# PIC32CX0525SG12144 register map
Vendor: Microchip Technology; Series: 0525SG12; File version: 0
CPU: CM4 r1p0, little endian, no MPU, no FPU, 3 interrupt priority bits, 172 interrupts
Registers are 32-bit, read-write, reset 0x0 unless marked. A register's access mark holds for its fields unless they carry their own. Offsets are from the block's base; [hi:lo] are bit positions; {n}, {i} and the like mark numbered series; 'fields as' and 'values as' point back to an identical list.

## ESPI_SMVW00_10 — The ESPI VW Channel permits the System to emulate a set of wires that interconnect the system Core Logic with the EC
Base 0x400F9E00; register names take the prefix ESPI_SMVW00_1_
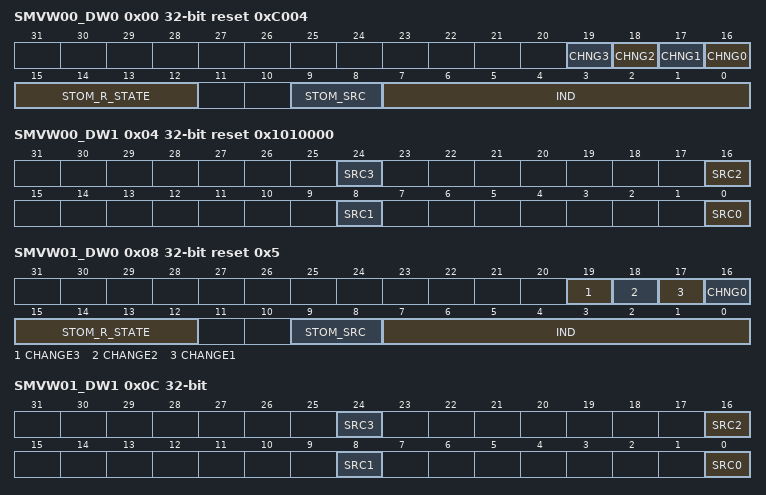
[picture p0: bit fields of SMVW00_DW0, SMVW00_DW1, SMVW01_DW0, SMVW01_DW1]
0x00 SMVW00_DW0 reset 0xC004 — Slave-to-Master Virtual Wire 0 Register (DWord 0)
  [n+16] CHNG{n} (n=0..3) — This bit is set to 1 whenever the value in Bit{n} in this register changes. This bit is set to 0 whenever the 4 data bits in this register are transmitted to the Host by a Slave-to-Master Virtual Wire transaction. It is also set to 0 when this entire register is reset, ignoring any change in the data bit value caused by the reset event.
  [15:12] STOM_R_STATE — The four bits in this field are loaded into SRC0, SRC1, SRC2 and SRC3 when the reset signal selected by S2M RESET SRC is asserted. If STOM_SRC is set for RESET_SYS, the SRC bits are set to the default value of this field, rather than its programmed value, since this field is also reset on RESET_SYS.
  [9:8] STOM_SRC — This field determines which reset signal in addition to RESET_SYS resets SRC[3:0] in this register: 3=PLTRST. 2=RESET_SIO. 1=RESET_SYS. This is the only reset signal that will reset the SRC fields. 0=RESET_ESPI.
  [7:0] IND — The Index for SRC0, SRC1, SRC2 and SRC3. A write to this register that changes the value of any one or more of SRC0, SRC1, SRC2 or SRC3 will generate a Slave-to-Master Virtual Wire transaction with this index. Setting the INDEX field to 0 disables the register from generating any Virtual Wire traffic to the Master. Setting the INDEX field to 1 is illegal, since INDEX=1 is reserved for Serial IRQ.
0x04 SMVW00_DW1 reset 0x1010000 — Slave-to-Master Virtual Wire 0 Register (DWord 1)
  [8n] SRC{n} (n=0..3) — Slave-to-Master data for Bit Position {n} for the virtual wire associated with the index defined by INDEX. The most recent value of this bit is transmitted to the Master, even if the bit changes multiple times before the Master issues the Virtual Wire read transaction.
0x08 SMVW01_DW0 reset 0x5 — Slave-to-Master Virtual Wire 1 Register (DWord 0)
  [19] CHANGE3 — This bit is set to 1 whenever the value in Bit3 in this register changes. This bit is set to 0 whenever the 4 data bits in this register are transmitted to the Host by a Slave-to-Master Virtual Wire transaction. It is also set to 0 when this entire register is reset, ignoring any change in the data bit value caused by the reset event.
  [18] CHANGE2 — This bit is set to 1 whenever the value in Bit2 in this register changes. This bit is set to 0 whenever the 4 data bits in this register are transmitted to the Host by a Slave-to-Master Virtual Wire transaction. It is also set to 0 when this entire register is reset, ignoring any change in the data bit value caused by the reset event.
  [17] CHANGE1 — This bit is set to 1 whenever the value in Bit1 in this register changes. This bit is set to 0 whenever the 4 data bits in this register are transmitted to the Host by a Slave-to-Master Virtual Wire transaction. It is also set to 0 when this entire register is reset, ignoring any change in the data bit value caused by the reset event.
  [16] CHNG0 — This bit is set to 1 whenever the value in Bit0 in this register changes. This bit is set to 0 whenever the 4 data bits in this register are transmitted to the Host by a Slave-to-Master Virtual Wire transaction. It is also set to 0 when this entire register is reset, ignoring any change in the data bit value caused by the reset event.
  [15:12] STOM_R_STATE — The four bits in this field are loaded into SRC0, SRC1, SRC2 and SRC3 when the reset signal selected by S2M RESET SRC is asserted. If STOM_SRC is set for RESET_SYS, the SRC bits are set to the default value of this field, rather than its programmed value, since this field is also reset on RESET_SYS.
  [9:8] STOM_SRC — This field determines which reset signal in addition to RESET_SYS resets SRC[3:0] in this register: 3=PLTRST. 2=RESET_SIO. 1=RESET_SYS. This is the only reset signal that will reset the SRC fields. 0=RESET_ESPI.
  [7:0] IND — The Index for SRC0, SRC1, SRC2 and SRC3. A write to this register that changes the value of any one or more of SRC0, SRC1, SRC2 or SRC3 will generate a Slave-to-Master Virtual Wire transaction with this index. Setting the INDEX field to 0 disables the register from generating any Virtual Wire traffic to the Master. Setting the INDEX field to 1 is illegal, since INDEX=1 is reserved for Serial IRQ.
0x0C SMVW01_DW1 — Slave-to-Master Virtual Wire 1 Register (DWord 1)
  fields as SMVW00_DW1
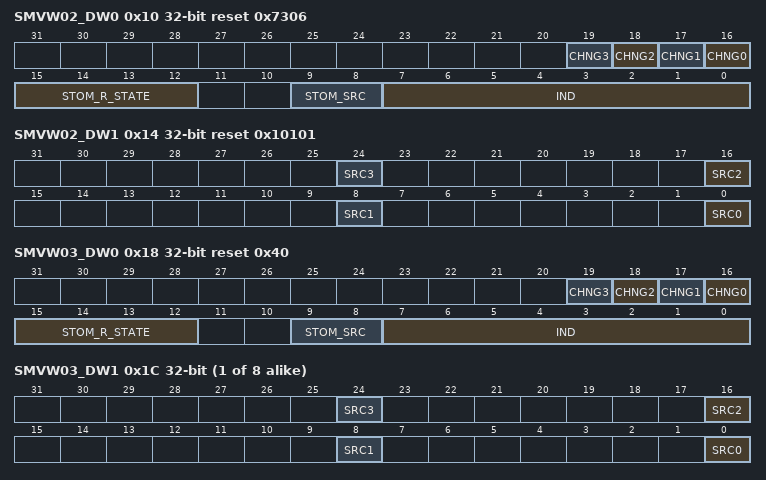
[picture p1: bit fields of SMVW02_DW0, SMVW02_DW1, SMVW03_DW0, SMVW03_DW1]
0x10 SMVW02_DW0 reset 0x7306 — Slave-to-Master Virtual Wire 2 Register (DWord 0)
  fields as SMVW00_DW0
0x14 SMVW02_DW1 reset 0x10101 — Slave-to-Master Virtual Wire 2 Register (DWord 1)
  fields as SMVW00_DW1
0x18 SMVW03_DW0 reset 0x40 — Slave-to-Master Virtual Wire 3 Register (DWord 0)
  fields as SMVW00_DW0
{0x4+8i} SMVW{i:02}_DW1 (i=3..10) — Slave-to-Master Virtual Wire {i} Register (DWord 1)
  fields as SMVW00_DW1
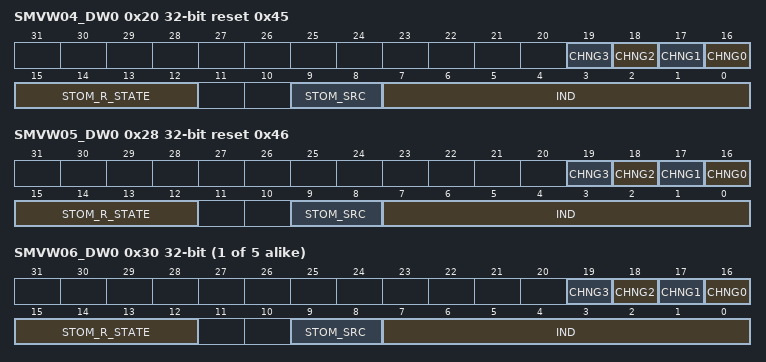
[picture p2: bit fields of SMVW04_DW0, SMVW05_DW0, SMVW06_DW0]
0x20 SMVW04_DW0 reset 0x45 — Slave-to-Master Virtual Wire 4 Register (DWord 0)
  fields as SMVW00_DW0
0x28 SMVW05_DW0 reset 0x46 — Slave-to-Master Virtual Wire 5 Register (DWord 0)
  fields as SMVW00_DW0
{0x0+8i} SMVW{i:02}_DW0 (i=6..10) — Slave-to-Master Virtual Wire {i} Register (DWord 0)
  fields as SMVW00_DW0
